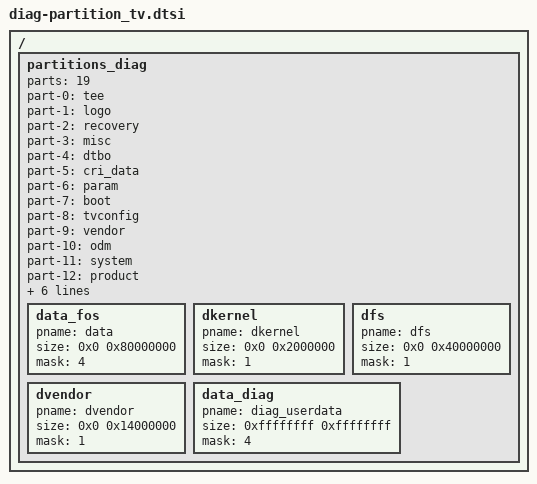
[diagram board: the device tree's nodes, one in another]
/*
 * Amlogic partition set for normal
 *
 * Copyright (c) 2017-2017 Amlogic Ltd
 *
 * This file is licensed under a dual GPLv2 or BSD license.
 *
 */

#include "firmware_system.dtsi"

/ {
    partitions_diag: partitions_diag{
		parts = <19>;
		part-0 = <&tee>;
		part-1 = <&logo>;
		part-2 = <&recovery>;
		part-3 = <&misc>;
		part-4 = <&dtbo>;
		part-5 = <&cri_data>;
		part-6 = <&param>;
		part-7 = <&boot>;
		part-8 = <&tvconfig>;
		part-9 = <&vendor>;
		part-10 = <&odm>;
		part-11 = <&system>;
		part-12 = <&product>;
		part-13 = <&cache>;
		part-14 = <&data_fos>;
		part-15 = <&dkernel>;
		part-16 = <&dfs>;
		part-17 = <&dvendor>;
		part-18 = <&data_diag>;

		data_fos:data_fos
		{
			pname = "data";
			size = <0x0 0x80000000>;
			mask = <4>;
		};
		dkernel:dkernel
		{
			pname = "dkernel";
			size = <0x0 0x2000000>;
			mask = <1>;
		};
		dfs:dfs
		{
			pname = "dfs";
			size = <0x0 0x40000000>;
			mask = <1>;
		};
		dvendor:dvendor
		{
			pname = "dvendor";
			size = <0x0 0x14000000>;
			mask = <1>;
		};
		data_diag:data_diag
		{
			pname = "diag_userdata";
			size = <0xffffffff 0xffffffff>;
			mask = <4>;
		};
	};
};/* end of / */
